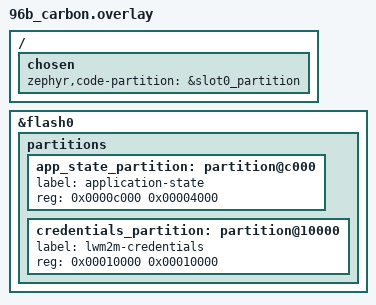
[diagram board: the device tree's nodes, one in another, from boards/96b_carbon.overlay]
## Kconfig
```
# Copyright (c) 2017 Linaro Limited
#
# SPDX-License-Identifier: Apache-2.0
#

mainmenu "Linaro FOTA configuration"

config ZEPHYR_BASE
	string
	option env="ZEPHYR_BASE"

config APPLICATION_BASE
	string
	option env="PROJECT_BASE"

source "$ZEPHYR_BASE/Kconfig.zephyr"

config FOTA_DEVICE
	bool "Enable FOTA device settings"
	default y
	select FOTA_DEVICE_SOC_SERIES_NRF52X if SOC_SERIES_NRF52X
	select FOTA_DEVICE_SOC_SERIES_STM32F4X if SOC_SERIES_STM32F4X
	help
	  Main config to enable device specific settings

config FOTA_DEVICE_SOC_SERIES_NRF52X
	bool "Nordic Semiconductor nRF52 FOTA settings"
	select TEST_RANDOM_GENERATOR
	select PWM_NRF5_SW
	default n

config FOTA_DEVICE_SOC_SERIES_STM32F4X
	bool "STM32F4x FOTA settings"
	select TEST_RANDOM_GENERATOR
	select PWM_STM32
	default n

config SYS_LOG_FOTA_LEVEL
	int "FOTA log level"
	depends on SYS_LOG && FOTA_DEVICE
	default 0
	range 0 4
	help
	  Set the log level for the FOTA library.

	  The available levels are:

	  - 0 OFF: do not write
	  - 1 ERROR: only write SYS_LOG_ERR
	  - 2 WARNING: write SYS_LOG_WRN in addition to previous level
	  - 3 INFO: write SYS_LOG_INF in addition to previous levels
	  - 4 DEBUG: write SYS_LOG_DBG in addition to previous levels

source "$APPLICATION_BASE/Kconfig.app"
```

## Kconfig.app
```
# Copyright (c) 2017 Linaro Limited
#
# SPDX-License-Identifier: Apache-2.0
#

config APP_PWM_WHITE
	bool
	prompt "Enable dedicated PWM for white color"
	default y

if APP_PWM_WHITE

config APP_PWM_WHITE_DEV
	string
	prompt "PWM device name used for white"

config APP_PWM_WHITE_PIN
	int
	prompt "PWM pin number used for white"
	default 0

config APP_PWM_WHITE_PIN_CEILING
	int
	prompt "PWM pin level ceiling"
	default 255
	range 1 255

endif # APP_PWM_WHITE
```

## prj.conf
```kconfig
CONFIG_BOOT_BANNER=y
CONFIG_BUILD_TIMESTAMP=y
CONFIG_REBOOT=y
CONFIG_FLASH=y

# Mesh uses system workqueue
CONFIG_SYSTEM_WORKQUEUE_STACK_SIZE=3072

# Bluetooth
CONFIG_BT=y
CONFIG_BT_OBSERVER=y
CONFIG_BT_BROADCASTER=y
CONFIG_BT_PERIPHERAL=y
CONFIG_BT_TINYCRYPT_ECC=y

# BT Buffers
CONFIG_BT_RX_BUF_COUNT=30
CONFIG_BT_L2CAP_RX_MTU=69
CONFIG_BT_L2CAP_TX_MTU=69
CONFIG_BT_L2CAP_TX_BUF_COUNT=5

# BT Controller
CONFIG_BT_CTLR_DUP_FILTER_LEN=0
CONFIG_BT_CTLR_LE_ENC=n
CONFIG_BT_CTLR_LE_PING=n
CONFIG_BT_CTLR_DATA_LENGTH=n
CONFIG_BT_CTLR_PHY=n
CONFIG_BT_CTLR_CHAN_SEL_2=n
CONFIG_BT_CTLR_MIN_USED_CHAN=n
CONFIG_BT_CTLR_ADV_EXT=n
CONFIG_BT_CTLR_PRIVACY=n

# BT Mesh
CONFIG_BT_MESH=y
CONFIG_BT_MESH_RELAY=y
CONFIG_BT_MESH_LOW_POWER=n
CONFIG_BT_MESH_FRIEND=n
CONFIG_BT_MESH_LOCAL_INTERFACE=y
CONFIG_BT_MESH_ADV_BUF_COUNT=20
CONFIG_BT_MESH_MSG_CACHE_SIZE=20

CONFIG_BT_MESH_PB_GATT=y
CONFIG_BT_MESH_PB_ADV=y
CONFIG_BT_MESH_GATT_PROXY=y

CONFIG_BT_MESH_SUBNET_COUNT=2
CONFIG_BT_MESH_APP_KEY_COUNT=2
CONFIG_BT_MESH_MODEL_GROUP_COUNT=2
CONFIG_BT_MESH_LABEL_COUNT=3

# General
CONFIG_MINIMAL_LIBC_EXTENDED=y

# FOTA
CONFIG_FOTA_DEVICE=y

# APP
CONFIG_APP_PWM_WHITE=y

CONFIG_BT_DEVICE_NAME="Zephyr BT Mesh Node"

# PWM
CONFIG_PWM=y
#CONFIG_SYS_LOG_PWM_LEVEL=4

# Logging
CONFIG_SYS_LOG=y
CONFIG_SYS_LOG_SHOW_COLOR=y
CONFIG_SYS_LOG_EXT_HOOK=y
CONFIG_SYS_LOG_FOTA_LEVEL=1

# Add flash RW to MPU
CONFIG_MPU_ALLOW_FLASH_WRITE=y

## Debug helpers
# Bluetooth (when enabled) debug
#CONFIG_BT_DEBUG_LOG=y
#CONFIG_BT_DEBUG_HCI_DRIVER=y
#CONFIG_BT_MESH_IV_UPDATE_TEST=y
#CONFIG_BT_DEBUG_MONITOR=y
#CONFIG_BT_MESH_DEBUG=y
#CONFIG_BT_MESH_DEBUG_PROV=y
#CONFIG_BT_MESH_DEBUG_PROXY=y
#CONFIG_BT_MESH_DEBUG_BEACON=y
#CONFIG_BT_MESH_DEBUG_NET=y
#CONFIG_BT_MESH_DEBUG_TRANS=y
#CONFIG_BT_MESH_DEBUG_LOW_POWER=y
#CONFIG_BT_MESH_DEBUG_FRIEND=y
#CONFIG_BT_MESH_DEBUG_MODEL=y
#CONFIG_BT_MESH_DEBUG_ACCESS=y
#CONFIG_BT_MESH_DEBUG_CRYPTO=y
#CONFIG_BT_MESH_DEBUG_ADV=y
#CONFIG_BT_MESH_SELF_TEST=y
#CONFIG_INIT_STACKS=y
#CONFIG_STACK_USAGE=y
```

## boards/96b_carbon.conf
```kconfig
# HW settings
CONFIG_TEXT_SECTION_OFFSET=0x100
# CONFIG_I2C is not set

# PWM
CONFIG_PWM_STM32_3=y
CONFIG_PWM_STM32_3_DEV_NAME="PWM_3"

# APP
CONFIG_APP_PWM_WHITE_DEV="PWM_3"
CONFIG_APP_PWM_WHITE_PIN=1
```

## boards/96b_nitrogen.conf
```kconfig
# HW settings
CONFIG_TEXT_SECTION_OFFSET=0x100

# PWM
CONFIG_PWM_NRF5_SW_0_DEV_NAME="PWM_0"

# APP
CONFIG_APP_PWM_WHITE_DEV="PWM_0"
CONFIG_APP_PWM_WHITE_PIN=4
CONFIG_APP_PWM_WHITE_PIN_CEILING=255
```

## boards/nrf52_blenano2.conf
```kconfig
# HW settings
CONFIG_TEXT_SECTION_OFFSET=0x100

# PWM
CONFIG_PWM_NRF5_SW_0_DEV_NAME="PWM_0"

# APP
CONFIG_APP_PWM_WHITE_DEV="PWM_0"
CONFIG_APP_PWM_WHITE_PIN=5
CONFIG_APP_PWM_WHITE_PIN_CEILING=255
```

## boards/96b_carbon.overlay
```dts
/ {
	chosen {
		zephyr,code-partition = &slot0_partition;
	};
};

&flash0 {
	partitions {
		app_state_partition: partition@c000 {
			label = "application-state";
			reg = <0x0000c000 0x00004000>;
		};

		credentials_partition: partition@10000 {
			label = "lwm2m-credentials";
			reg = <0x00010000 0x00010000>;
		};
	};
};
```

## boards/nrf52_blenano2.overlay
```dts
/ {
	chosen {
		zephyr,code-partition = &slot0_partition;
	};
};

&flash0 {
	partitions {
		app_state_partition: partition@7d000 {
			label = "application-state";
			reg = <0x0007d000 0x2000>;
		};

		credentials_partition: partition@7f000 {
			label = "lwm2m-credentials";
			reg = <0x0007f000 0x1000>;
		};
	};
};
```

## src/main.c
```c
/*
 * Copyright (c) 2016-2017 Linaro Limited
 *
 * SPDX-License-Identifier: Apache-2.0
 */

#define SYS_LOG_DOMAIN "fota/main"
#define SYS_LOG_LEVEL CONFIG_SYS_LOG_FOTA_LEVEL
#include <logging/sys_log.h>

#include <zephyr.h>
#include <board.h>
#include <gpio.h>
#include <pwm.h>
#include <tc_util.h>

#include <bluetooth/bluetooth.h>
#include <bluetooth/mesh.h>

/* Local helpers and functions */
#include "tstamp_log.h"
#include "app_work_queue.h"
#include "mcuboot.h"
#include "product_id.h"

#define REPLY_EXP_RANGE 50

/* Force CID from Nordic as our main use cases are nRF5-based devices */
#define CID_NORDIC 0x0059

struct device *flash_dev;

/* Blink */
struct pwm_blink_ctx {
	struct k_delayed_work work;
	u32_t delay;
	u32_t count;
};

struct gpio_blink_ctx {
	struct k_delayed_work work;
	struct device *gpio;
	u32_t gpio_pin;
	u32_t count;
};

static struct pwm_blink_ctx pwm_blink_context;
static struct gpio_blink_ctx prov_blink_context;

#define PROV_BLINK_DELAY	K_SECONDS(1)

/* PWM */

/* 100 is more than enough for it to be flicker free */
#define PWM_PERIOD (USEC_PER_SEC / 100)

static struct device *pwm_white;
static u8_t white_current;

static u32_t scale_pulse(u8_t level, u8_t ceiling)
{
	if (level && ceiling) {
		/* Scale level based on ceiling and return period */
		return PWM_PERIOD / 255 * level * ceiling / 255;
	}

	return 0;
}

static int write_pwm_pin(struct device *pwm_dev, u32_t pwm_pin,
			 u8_t level, u8_t ceiling)
{
	u32_t pulse = scale_pulse(level, ceiling);

	SYS_LOG_DBG("Set PWM %d: level %d, ceiling %d, pulse %lu",
				pwm_pin, level, ceiling, pulse);

	return pwm_pin_set_usec(pwm_dev, pwm_pin, PWM_PERIOD, pulse);
}

static int update_pwm(u8_t dimmer)
{
	u8_t white;
	int ret = 0;

	SYS_LOG_DBG("dimmer: %d", dimmer);

	if (dimmer < 0) {
		dimmer = 0;
	}
	if (dimmer > 100) {
		dimmer = 100;
	}

	white = 255 * dimmer / 100;
	if (white != white_current) {
		white_current = white;
		ret = write_pwm_pin(pwm_white, CONFIG_APP_PWM_WHITE_PIN, white,
					CONFIG_APP_PWM_WHITE_PIN_CEILING);
		if (ret) {
			SYS_LOG_ERR("Failed to update white PWM");
			return ret;
		}
	}

	return ret;
}

static int init_pwm(void)
{
	pwm_white = device_get_binding(CONFIG_APP_PWM_WHITE_DEV);
	if (!pwm_white) {
		SYS_LOG_ERR("Failed to get PWM device used for white");
		return -ENODEV;
	}

	return 0;
}

/* Bluetooth Mesh */

static struct bt_mesh_cfg cfg_srv = {
#if defined(CONFIG_BT_MESH_RELAY)
	.relay = BT_MESH_RELAY_ENABLED,
#else
	.relay = BT_MESH_RELAY_NOT_SUPPORTED,
#endif
	.beacon = BT_MESH_BEACON_ENABLED,
	.frnd = BT_MESH_FRIEND_NOT_SUPPORTED,
#if defined(CONFIG_BT_MESH_GATT_PROXY)
	.gatt_proxy = BT_MESH_GATT_PROXY_ENABLED,
#else
	.gatt_proxy = BT_MESH_GATT_PROXY_NOT_SUPPORTED,
#endif
	/*
	 * Here also used when comparing with received msgs, even if
	 * not ideal (as the only way to know the original TTL is via
	 * heartbeat messages).
	 */
	.default_ttl = 5,

	/* 3 transmissions with 20ms interval */
	.net_transmit = BT_MESH_TRANSMIT(2, 20),
	.relay_retransmit = BT_MESH_TRANSMIT(2, 20),
};

static struct bt_mesh_health health_srv = {
};

static struct bt_mesh_model_pub gen_onoff_pub;

static u8_t onoff_state;

static void gen_onoff_reply_status(struct bt_mesh_model *model,
				   struct bt_mesh_msg_ctx *src_ctx)
{
	/* 2 for msg_init, 4 for OnOff Status and 4 for TransMIC */
	struct net_buf_simple *msg = NET_BUF_SIMPLE(2 + 4 + 4);
	struct bt_mesh_msg_ctx ctx;
	int exp_ms;

	/* Reuse source ctx (addr is already the right remote) */
	memcpy(&ctx, src_ctx, sizeof(ctx));
	ctx.send_ttl = cfg_srv.default_ttl;

	/* Generic OnOff Status */
	bt_mesh_model_msg_init(msg, BT_MESH_MODEL_OP_2(0x82, 0x04));
	net_buf_simple_add_u8(msg, onoff_state);
	SYS_LOG_DBG("Sending OnOff Status (state: %d)", onoff_state);

	/*
	 * HACK: add delay to avoid overloading network. Suggestion
	 * from spec is to use something between 20 to 50 ms / 200 ms.
	 * TODO: change to be handled by a worker instead
	 */
	exp_ms = (REPLY_EXP_RANGE / 2) + sys_rand32_get() % REPLY_EXP_RANGE;
	k_sleep(exp_ms);

	SYS_LOG_DBG("Remote Address: %x, Send TTL: %d",
				ctx.addr, ctx.send_ttl);
	if (bt_mesh_model_send(model, &ctx, msg, NULL, NULL)) {
		SYS_LOG_ERR("Unable to send Generic OnOff Status message");
	}
}

static void gen_onoff_get(struct bt_mesh_model *model,
			  struct bt_mesh_msg_ctx *ctx,
			  struct net_buf_simple *buf)
{
	gen_onoff_reply_status(model, ctx);
}

static int onoff_set(struct bt_mesh_model *model,
		     struct bt_mesh_msg_ctx *ctx,
		     struct net_buf_simple *buf)
{
	u8_t onoff;
	u8_t tid;
	int delay = 0;

	SYS_LOG_DBG("recv_ttl: %d", ctx->recv_ttl);

	/* TODO: Transition Time and Delay */
	onoff = net_buf_simple_pull_u8(buf);
	tid = net_buf_simple_pull_u8(buf);
	SYS_LOG_DBG("onoff: %d, tid: %d", onoff, tid);

	if (onoff != onoff_state) {
		onoff_state = onoff;
		SYS_LOG_DBG("Internal light state changed to %d", onoff_state);

		if (onoff_state) {
			/* Use TTL to define the blink delay */
			/* TODO: Fetch TTL from the sender */
			delay = cfg_srv.default_ttl - ctx->recv_ttl;
			if (delay < 0) {
				delay = 0;
			}
		}

		/* Remove possible pending previous work */
		k_delayed_work_cancel(&pwm_blink_context.work);

		SYS_LOG_DBG("Set Blink delay to %d seconds", delay);
		pwm_blink_context.count = 1;
		pwm_blink_context.delay = 50 * (delay * 4);

		/* TODO: Use model delay instead of 10 ms */
		k_delayed_work_submit(&pwm_blink_context.work, 10);

		return 1;
	}

	return 0;
}

static void gen_onoff_set(struct bt_mesh_model *model,
			  struct bt_mesh_msg_ctx *ctx,
			  struct net_buf_simple *buf)
{
	if (onoff_set(model, ctx, buf)) {
		/* Send back ACK/Status */
		gen_onoff_reply_status(model, ctx);
	}
}

static void gen_onoff_set_unack(struct bt_mesh_model *model,
				struct bt_mesh_msg_ctx *ctx,
				struct net_buf_simple *buf)
{
	onoff_set(model, ctx, buf);
}

static const struct bt_mesh_model_op gen_onoff_op[] = {
	{ BT_MESH_MODEL_OP_2(0x82, 0x01), 0, gen_onoff_get },
	{ BT_MESH_MODEL_OP_2(0x82, 0x02), 2, gen_onoff_set },
	{ BT_MESH_MODEL_OP_2(0x82, 0x03), 2, gen_onoff_set_unack },
	BT_MESH_MODEL_OP_END,
};

static struct bt_mesh_model root_models[] = {
	BT_MESH_MODEL_CFG_SRV(&cfg_srv),
	BT_MESH_MODEL_HEALTH_SRV(&health_srv),
	BT_MESH_MODEL(BT_MESH_MODEL_ID_GEN_ONOFF_SRV, gen_onoff_op,
		      &gen_onoff_pub, NULL),
};

static struct bt_mesh_model vnd_models[] = {
};

static struct bt_mesh_elem elements[] = {
	BT_MESH_ELEM(0, root_models, vnd_models),
};

static const struct bt_mesh_comp comp = {
	.cid = CID_NORDIC,
	.elem = elements,
	.elem_count = ARRAY_SIZE(elements),
};

static void prov_complete(void)
{
	SYS_LOG_INF("Provisioning completed!");

#if defined(BT_GPIO_PIN) && defined(BT_GPIO_PORT)
	prov_blink_context.gpio = device_get_binding(BT_GPIO_PORT);
	prov_blink_context.gpio_pin = BT_GPIO_PIN;
#elif defined(LED0_GPIO_PIN) && defined(LED0_GPIO_PORT)
	/* Use LED0 in case there is no dedicated LED for BT */
	prov_blink_context.gpio = device_get_binding(LED0_GPIO_PORT);
	prov_blink_context.gpio_pin = LED0_GPIO_PIN;
#endif

	if (prov_blink_context.gpio) {
		gpio_pin_configure(prov_blink_context.gpio,
				   prov_blink_context.gpio_pin,
				   GPIO_DIR_OUT);

		app_wq_submit_delayed(&prov_blink_context.work,
				      PROV_BLINK_DELAY);
	}
}

static uint8_t dev_uuid[16];

/* TODO: support either blink or number by default */
static const struct bt_mesh_prov prov = {
	.uuid = dev_uuid,
	.output_actions = BT_MESH_NO_OUTPUT,
	.complete = prov_complete,
};

static void bt_ready(int err)
{
	u32_t id_number;
	int i;

	if (err) {
		SYS_LOG_ERR("Bluetooth init failed (err %d)", err);
		return;
	}

	SYS_LOG_INF("Bluetooth initialized");

	/* Set Device UUID based on the product id number */
	id_number = product_id_get()->number;
	for (i = 0; i < sizeof(dev_uuid); i++) {
		dev_uuid[i] = id_number >> 8 * i & 0xff;
	}

	err = bt_mesh_init(&prov, &comp);
	if (err) {
		SYS_LOG_ERR("Initializing mesh failed (err %d)", err);
		return;
	}

	SYS_LOG_INF("Mesh initialized");
}

static void pwm_blink_handler(struct k_work *work)
{
	struct pwm_blink_ctx *blink =
			CONTAINER_OF(work, struct pwm_blink_ctx, work);

	if (onoff_state) {
		if (blink->delay) {
			/* Blink depending on the value */
			update_pwm(100 * (blink->count++ % 2));
			k_delayed_work_submit(&blink->work, blink->delay);
		} else {
			update_pwm(100);
		}
	} else {
		/* Just turn it off */
		update_pwm(0);
		blink->delay = 0;
	}
}

static void prov_blink_handler(struct k_work *work)
{
	struct gpio_blink_ctx *blink =
		CONTAINER_OF(work, struct gpio_blink_ctx, work);

	gpio_pin_write(blink->gpio, blink->gpio_pin, blink->count++ % 2);
	app_wq_submit_delayed(&blink->work, PROV_BLINK_DELAY);
}

void main(void)
{
	int ret;

	tstamp_hook_install();
	app_wq_init();

	/* Blinking pattern handler */
	k_delayed_work_init(&pwm_blink_context.work, pwm_blink_handler);

	/* Visual feedback for provisioning */
	k_delayed_work_init(&prov_blink_context.work, prov_blink_handler);

	SYS_LOG_INF("Bluetooth Mesh Smart Light Bulb");
	SYS_LOG_INF("Device: %s, Serial: %x",
		    product_id_get()->name, product_id_get()->number);

	TC_PRINT("Initializing PWM\n");
	if (init_pwm()) {
		_TC_END_RESULT(TC_FAIL, "init_pwm");
		TC_END_REPORT(TC_FAIL);
		return;
	}
	_TC_END_RESULT(TC_PASS, "init_pwm");

	TC_PRINT("Initializing Bluetooth Stack\n");
	ret = bt_enable(bt_ready);
	if (ret) {
		SYS_LOG_ERR("Bluetooth init failed (err %d)", ret);
		_TC_END_RESULT(TC_FAIL, "init_bt_enable");
		TC_END_REPORT(TC_FAIL);
		return;
	}
	_TC_END_RESULT(TC_PASS, "init_bt_enable");

	TC_END_REPORT(TC_PASS);

	/*
	 * From this point on, just handle work.
	 */
	app_wq_run();
}
```

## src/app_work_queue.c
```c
/*
 * Copyright (c) 2016 Intel Corporation
 * Copyright (c) 2016 Wind River Systems, Inc.
 * Copyright (c) 2017 Linaro, Inc.
 *
 * SPDX-License-Identifier: Apache-2.0
 */

/*
 * This file copies the work queue implementation from Zephyr, but
 * allows users to just start running the work queue on a desired
 * thread.
 *
 * This is useful to avoid allocating two thread stacks if one thread
 * (in our case, the main thread) isn't using its stack for the
 * application's lifetime, and could be doing useful work instead.
 *
 * TODO: propose a more upstream-friendly way to support this.
 */

#include "app_work_queue.h"

static struct k_work_q app_queue;

struct k_work_q *_app_q = &app_queue;

void app_wq_init(void)
{
	k_queue_init(&_app_q->queue);
}

void app_wq_run(void)
{
	while (1) {
		struct k_work *work;
		k_work_handler_t handler;

		work = k_queue_get(&_app_q->queue, K_FOREVER);

		handler = work->handler;

		/* Reset pending state so it can be resubmitted by handler */
		if (atomic_test_and_clear_bit(work->flags,
					       K_WORK_STATE_PENDING)) {
			handler(work);
		}

		/* Make sure we don't hog up the CPU if the QUEUE never (or
		 * very rarely) gets empty.
		 */
		k_yield();
	}
}
```

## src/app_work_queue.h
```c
/*
 * Copyright (c) 2017 Linaro Limited
 *
 * SPDX-License-Identifier: Apache-2.0
 */

#ifndef __FOTA_APP_WORK_QUEUE_H__
#define __FOTA_APP_WORK_QUEUE_H__

/**
 * @file
 * @brief FOTA application work queue
 *
 * This is a single work queue which can be used for sleeping tasks
 * within this application. It is primarily intended to schedule work
 * items which must run sequentially from different application-level
 * threads.
 *
 * Work handlers submitted to this queue may sleep or yield.
 *
 * Work may be submitted to this queue only by threads started from
 * main().
 */

#include <zephyr.h>
#include <zephyr/types.h>

/* For internal use, do not touch. */
extern struct k_work_q *_app_q;

/**
 * @brief Initialize the application work queue.
 *
 * Work may be submitted to the queue after this function returns. It
 * will not be processed until app_wq_run() is called.
 *
 * @see app_wq_run()
 */
void app_wq_init(void);

/**
 * @brief Start handling work queue events in the current thread.
 *
 * Unlike k_work_q_start(), this does not create a new thread;
 * instead, it runs in the caller's.
 *
 * @see k_work_q_start()
 */
FUNC_NORETURN
void app_wq_run(void);

/**
 * @brief Submit work to the application work queue thread.
 * @param work Work to submit
 * @see k_work_submit_to_queue()
 */
static inline void app_wq_submit(struct k_work *work)
{
	k_work_submit_to_queue(_app_q, work);
}

/**
 * @brief Submit delayed work to the application work queue thread.
 * @param work     Work to submit
 * @param delay_ms Delay in milliseconds
 * @return k_delayed_work_submit_to_queue() return value.
 * @see k_delayed_work_submit_to_queue()
 */
static inline int app_wq_submit_delayed(struct k_delayed_work *work,
					s32_t delay_ms)
{
	return k_delayed_work_submit_to_queue(_app_q, work, delay_ms);
}

#endif /* __FOTA_APP_WORK_QUEUE_H__ */
```

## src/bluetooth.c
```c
/*
 * Copyright (c) 2016-2017 Linaro Limited
 *
 * SPDX-License-Identifier: Apache-2.0
 */

#define SYS_LOG_DOMAIN "fota/bluetooth"
#define SYS_LOG_LEVEL SYS_LOG_LEVEL_DEBUG
#include <logging/sys_log.h>

#include <zephyr/types.h>
#include <stddef.h>
#include <errno.h>
#include <zephyr.h>
#include <gpio.h>
#include <misc/reboot.h>
#include <init.h>
#include <soc.h>
#include <board.h>

#include <bluetooth/bluetooth.h>
#include <bluetooth/hci.h>
#include <bluetooth/storage.h>
#include <bluetooth/conn.h>

#include "product_id.h"

/* Any by default, can change depending on the hardware implementation */
static bt_addr_le_t bt_addr;

static ssize_t storage_read(const bt_addr_le_t *addr, u16_t key, void *data,
			       size_t length)
{
	if (addr) {
		return -ENOENT;
	}

	if (key == BT_STORAGE_ID_ADDR && length == sizeof(bt_addr)) {
		bt_addr_le_copy(data, &bt_addr);
		return sizeof(bt_addr);
	}

	return -EIO;
}

static ssize_t storage_write(const bt_addr_le_t *addr, u16_t key,
				const void *data, size_t length)
{
	return -ENOSYS;
}

static ssize_t storage_clear(const bt_addr_le_t *addr)
{
	return -ENOSYS;
}

static void set_own_bt_addr(void)
{
	int i;
	u8_t tmp;

	/*
	 * Generate a static BT addr using the unique product number.
	 */
	for (i = 0; i < 4; i++) {
		tmp = (product_id_get()->number >> i * 8) & 0xff;
		bt_addr.a.val[i] = tmp;
	}

	bt_addr.a.val[4] = 0xe7;
	bt_addr.a.val[5] = 0xd6;
}

static int bt_storage_init(void)
{
	static const struct bt_storage storage = {
		.read = storage_read,
		.write = storage_write,
		.clear = storage_clear,
	};

	bt_addr.type = BT_ADDR_LE_RANDOM;

	set_own_bt_addr();

	bt_storage_register(&storage);

	SYS_LOG_DBG("Bluetooth storage driver registered");

	return 0;
}

/* BT LE Connect/Disconnect callbacks */
static void set_bluetooth_led(bool state)
{
#if defined(BT_GPIO_PIN) && defined(BT_GPIO_PORT)
	struct device *gpio = device_get_binding(BT_GPIO_PORT);
	gpio_pin_configure(gpio, BT_GPIO_PIN, GPIO_DIR_OUT);
	gpio_pin_write(gpio, BT_GPIO_PIN, state);
#elif defined(LED0_GPIO_PIN) && defined(LED0_GPIO_PORT)
	/* Use LED0 in case there is no dedicated LED for BT */
	struct device *gpio = device_get_binding(LED0_GPIO_PORT);
	gpio_pin_configure(gpio, LED0_GPIO_PIN, GPIO_DIR_OUT);
	gpio_pin_write(gpio, LED0_GPIO_PIN, state);
#endif
}

static void connected(struct bt_conn *conn, u8_t err)
{
	if (err) {
		SYS_LOG_ERR("BT LE Connection failed: %u", err);
	} else {
		SYS_LOG_INF("BT LE Connected");
		set_bluetooth_led(1);
	}
}

static void disconnected(struct bt_conn *conn, u8_t reason)
{
	SYS_LOG_INF("BT LE Disconnected (reason %u)", reason);
	set_bluetooth_led(0);
}

static struct bt_conn_cb conn_callbacks = {
	.connected = connected,
	.disconnected = disconnected,
};

static int bt_network_init(struct device *dev)
{
	/* Storage used to provide a BT MAC based on the serial number */
	SYS_LOG_DBG("Setting Bluetooth MAC\n");
	bt_storage_init();
	bt_conn_cb_register(&conn_callbacks);
	return 0;
}

/* last priority in the POST_KERNEL init levels */
SYS_INIT(bt_network_init, APPLICATION, CONFIG_APPLICATION_INIT_PRIORITY);
```

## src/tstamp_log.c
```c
/*
 * Copyright (c) 2017 Linaro Limited
 * Copyright (c) 2010, 2013-2014 Wind River Systems, Inc.
 *
 * SPDX-License-Identifier: Apache-2.0
 */

#include "tstamp_log.h"

/*
 * Even though we don't actually log from this file, without this
 * define, sys_log.h will think it's inactive in this compilation
 * unit.
 */
#define SYS_LOG_LEVEL SYS_LOG_LEVEL_ERROR


#include <logging/sys_log.h>
#include <misc/printk.h>
#include <zephyr.h>

#include <stdarg.h>

static void tstamp_log_fn(const char *fmt, ...)
{
	va_list ap;
	u32_t up_ms = k_uptime_get_32();

	printk("[%07u] ", up_ms);

	va_start(ap, fmt);
	vprintk(fmt, ap);
	va_end(ap);
}

void tstamp_hook_install(void)
{
	syslog_hook_install(tstamp_log_fn);
}
```

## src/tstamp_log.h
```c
/*
 * Copyright (c) 2017 Linaro Limited
 *
 * SPDX-License-Identifier: Apache-2.0
 */

/**
 * @file
 * @brief Zephyr syslog backend hook that also prints timestamps.
 */

#ifndef __FOTA_TSTAMP_LOG_H__
#define __FOTA_TSTAMP_LOG_H__

#ifndef CONFIG_SYS_LOG_EXT_HOOK
static inline void tstamp_hook_install(void)
{
}
#else
/**
 * @brief Install timestamp backend hook.
 *
 * Calling this routine will modify Zephyr's syslog behavior to print
 * a timestamp before the log output. The timestamp is currently a
 * 32-bit monotonic uptime counter, in milliseconds.
 */
void tstamp_hook_install(void);
#endif	/* !defined(CONFIG_SYS_LOG_EXT_HOOK) */

#endif	/* __FOTA_TSTAMP_LOG_H__ */
```
